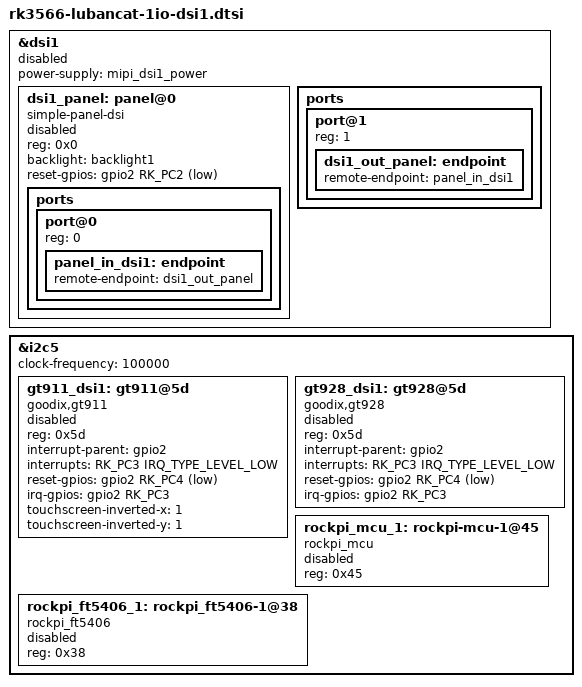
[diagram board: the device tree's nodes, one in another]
// SPDX-License-Identifier: (GPL-2.0+ OR MIT)
&dsi1 {
	status = "disabled";
	power-supply = <&mipi_dsi1_power>;
	#address-cells = <1>;
	#size-cells = <0>;

	dsi1_panel: panel@0 {
		status = "disabled";
		compatible = "simple-panel-dsi";
		reg = <0x0>;
		backlight = <&backlight1>;
		reset-gpios = <&gpio2 RK_PC2 GPIO_ACTIVE_LOW>;

		// enable-delay-ms = <35>;
		// prepare-delay-ms = <6>;
		// reset-delay-ms = <0>;
		// init-delay-ms = <20>;
		// unprepare-delay-ms = <0>;
		// disable-delay-ms = <20>;

		// size,width = <74>;
		// size,height = <133>;

		// dsi,flags = <(MIPI_DSI_MODE_VIDEO | MIPI_DSI_MODE_VIDEO_BURST | MIPI_DSI_MODE_LPM | MIPI_DSI_MODE_EOT_PACKET)>;
		// dsi,format = <MIPI_DSI_FMT_RGB888>;
		// dsi,lanes  = <4>;

		// panel-init-sequence = [
		// ];

		// panel-exit-sequence = [
		// ];

		// disp_timings: display-timings {
		// 	native-mode = <&dsi1_timing>;
		// 	dsi1_timing: timing {
		// 		clock-frequency = <131376000>;
		// 		hactive = <1080>;
		// 		vactive = <1920>;
		// 		hsync-len = <10>;
		// 		hback-porch = <20>;
		// 		hfront-porch = <10>;
		// 		vsync-len = <5>;
		// 		vback-porch = <20>;
		// 		vfront-porch = <10>;
		// 		hsync-active = <0>;
		// 		vsync-active = <0>;
		// 		de-active = <0>;
		// 		pixelclk-active = <0>;
		// 	};
		// };

		ports {
			#address-cells = <1>;
			#size-cells = <0>;
			port@0 {
				reg = <0>;
				panel_in_dsi1: endpoint {
					remote-endpoint = <&dsi1_out_panel>;
				};
			};
		};
	};

	ports {
		#address-cells = <1>;
		#size-cells = <0>;

		port@1 {
			reg = <1>;
			dsi1_out_panel: endpoint {
				remote-endpoint = <&panel_in_dsi1>;
			};
		};
	};
};

&i2c5 {
	status = "okay";
	clock-frequency = <100000>;
	#address-cells = <1>;
	#size-cells = <0>;

	gt911_dsi1: gt911@5d {
		status = "disabled";
		compatible = "goodix,gt911";
		reg = <0x5d>;
		interrupt-parent = <&gpio2>;
		interrupts = <RK_PC3 IRQ_TYPE_LEVEL_LOW>;
		reset-gpios = <&gpio2 RK_PC4 GPIO_ACTIVE_LOW>;
		irq-gpios = <&gpio2 RK_PC3 GPIO_ACTIVE_HIGH>;
		touchscreen-inverted-x = <1>;
		touchscreen-inverted-y = <1>;
	};

	gt928_dsi1: gt928@5d {
		status = "disabled";
		compatible = "goodix,gt928";
		reg = <0x5d>;
		interrupt-parent = <&gpio2>;
		interrupts = <RK_PC3 IRQ_TYPE_LEVEL_LOW>;
		reset-gpios = <&gpio2 RK_PC4 GPIO_ACTIVE_LOW>;
		irq-gpios = <&gpio2 RK_PC3 GPIO_ACTIVE_HIGH>;
	};

	rockpi_mcu_1: rockpi-mcu-1@45 {
		compatible = "rockpi_mcu";
		reg = <0x45>;
		status = "disabled";
	};

	rockpi_ft5406_1: rockpi_ft5406-1@38 {
		compatible = "rockpi_ft5406";
		reg = <0x38>;
		status = "disabled";
	};
};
